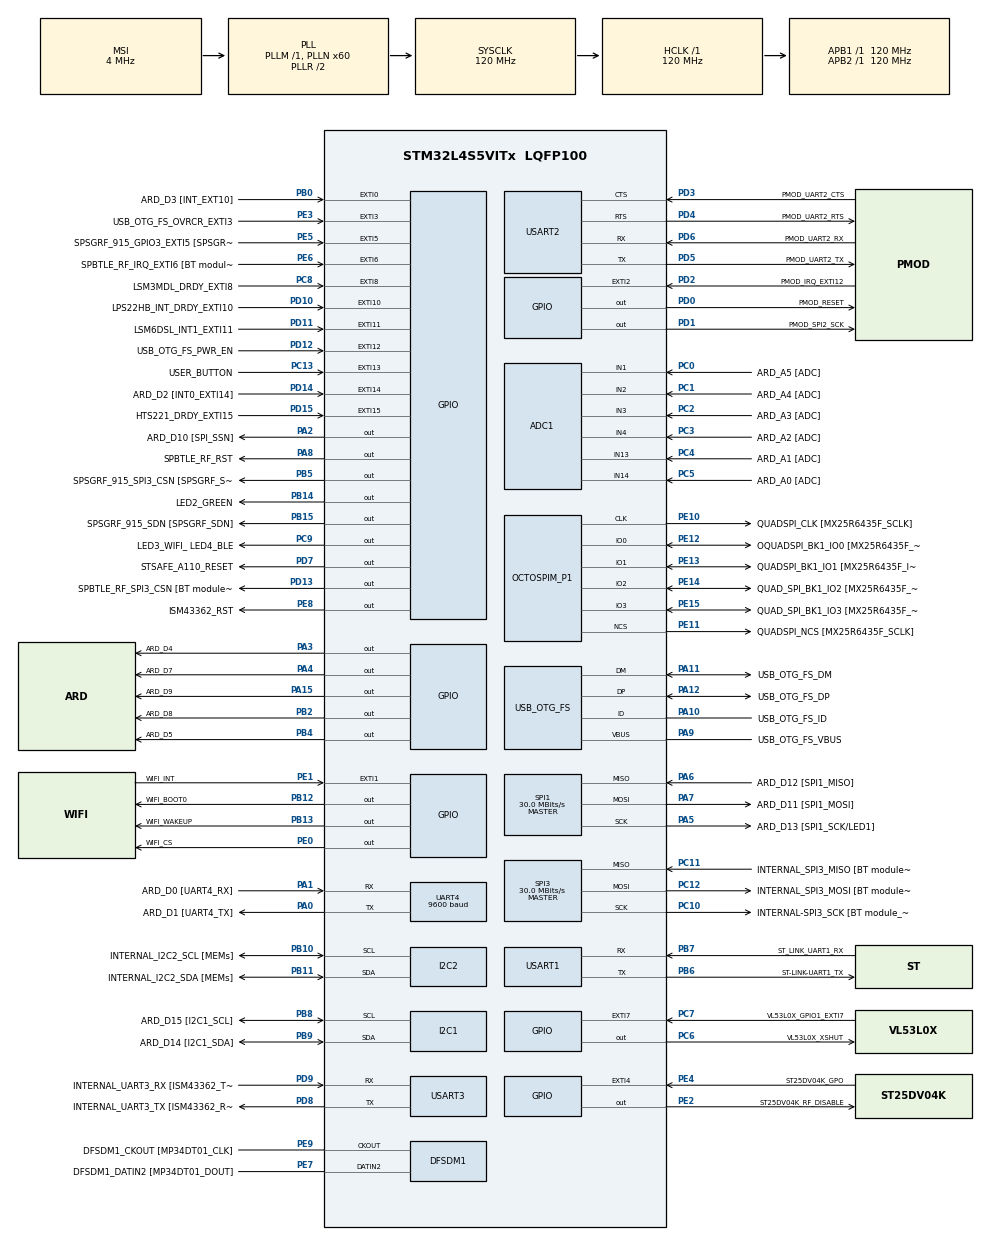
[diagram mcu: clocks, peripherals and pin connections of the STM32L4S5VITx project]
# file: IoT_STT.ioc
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ADC1.Channel-0\#ChannelRegularConversion=ADC_CHANNEL_1
ADC1.NbrOfConversionFlag=1
ADC1.OffsetNumber-0\#ChannelRegularConversion=ADC_OFFSET_NONE
ADC1.Rank-0\#ChannelRegularConversion=1
ADC1.SamplingTime-0\#ChannelRegularConversion=ADC_SAMPLETIME_2CYCLES_5
ADC1.master=1
I2C1.Timing=0x307075B1
I2C2.Timing=0x307075B1
Mcu.Family=STM32L4
Mcu.Name=STM32L4S5VITx
Mcu.Package=LQFP100
NVIC.EXTI15_10_IRQn=true\:0\:0\:false\:false\:true\:true\:true
NVIC.EXTI1_IRQn=true\:13\:0\:true\:false\:true\:true\:true
NVIC.EXTI9_5_IRQn=true\:0\:0\:false\:false\:true\:true\:true
NVIC.PriorityGroup=NVIC_PRIORITYGROUP_4
NVIC.SPI3_IRQn=true\:3\:0\:true\:false\:true\:true\:true
OCTOSPI1.MemoryType=HAL_OSPI_MEMTYPE_MACRONIX
PA0.GPIO_Label=ARD_D1 [UART4_TX]
PA0.GPIO_ModeDefaultPP=GPIO_MODE_AF_PP
PA0.GPIO_PuPd=GPIO_NOPULL
PA0.GPIO_Speed=GPIO_SPEED_FREQ_VERY_HIGH
PA0.Mode=Asynchronous
PA0.Signal=UART4_TX
PA1.GPIO_Label=ARD_D0 [UART4_RX]
PA1.GPIO_ModeDefaultPP=GPIO_MODE_AF_PP
PA1.GPIO_PuPd=GPIO_NOPULL
PA1.GPIO_Speed=GPIO_SPEED_FREQ_VERY_HIGH
PA1.Mode=Asynchronous
PA1.Signal=UART4_RX
PA10.GPIO_Label=USB_OTG_FS_ID
PA10.Mode=OTG/Dual_Role_Device
PA10.Signal=USB_OTG_FS_ID
PA11.GPIO_Label=USB_OTG_FS_DM
PA11.Mode=OTG/Dual_Role_Device
PA11.Signal=USB_OTG_FS_DM
PA12.GPIO_Label=USB_OTG_FS_DP
PA12.Mode=OTG/Dual_Role_Device
PA12.Signal=USB_OTG_FS_DP
PA13\ (JTMS/SWDIO).GPIO_Label=SYS_JTMS_SWDIO
PA13\ (JTMS/SWDIO).Mode=Serial_Wire
PA13\ (JTMS/SWDIO).Signal=SYS_JTMS-SWDIO
PA14\ (JTCK/SWCLK).GPIO_Label=SYS_JTCK_SWCLK
PA14\ (JTCK/SWCLK).Mode=Serial_Wire
PA14\ (JTCK/SWCLK).Signal=SYS_JTCK-SWCLK
PA15\ (JTDI).GPIO_Label=ARD_D9
PA15\ (JTDI).GPIO_ModeDefaultOutputPP=GPIO_MODE_OUTPUT_PP
PA15\ (JTDI).GPIO_PuPd=GPIO_NOPULL
PA15\ (JTDI).GPIO_Speed=GPIO_SPEED_FREQ_LOW
PA15\ (JTDI).PinState=GPIO_PIN_RESET
PA15\ (JTDI).Signal=GPIO_Output
PA2.GPIO_Label=ARD_D10 [SPI_SSN]
PA2.GPIO_ModeDefaultOutputPP=GPIO_MODE_OUTPUT_PP
PA2.GPIO_PuPd=GPIO_NOPULL
PA2.GPIO_Speed=GPIO_SPEED_FREQ_LOW
PA2.PinState=GPIO_PIN_RESET
PA2.Signal=GPIO_Output
PA3.GPIO_Label=ARD_D4
PA3.Signal=GPIO_Output
PA4.GPIO_Label=ARD_D7
PA4.Signal=GPIO_Output
PA5.GPIO_Label=ARD_D13 [SPI1_SCK/LED1]
PA5.GPIO_Mode=GPIO_MODE_AF_PP
PA5.GPIO_PuPd=GPIO_NOPULL
PA5.GPIO_Speed=GPIO_SPEED_FREQ_VERY_HIGH
PA5.Mode=Full_Duplex_Master
PA5.Signal=SPI1_SCK
PA6.GPIO_Label=ARD_D12 [SPI1_MISO]
PA6.GPIO_Mode=GPIO_MODE_AF_PP
PA6.GPIO_PuPd=GPIO_NOPULL
PA6.GPIO_Speed=GPIO_SPEED_FREQ_VERY_HIGH
PA6.Mode=Full_Duplex_Master
PA6.Signal=SPI1_MISO
PA7.GPIO_Label=ARD_D11 [SPI1_MOSI]
PA7.GPIO_Mode=GPIO_MODE_AF_PP
PA7.GPIO_PuPd=GPIO_NOPULL
PA7.GPIO_Speed=GPIO_SPEED_FREQ_VERY_HIGH
PA7.Mode=Full_Duplex_Master
PA7.Signal=SPI1_MOSI
PA8.GPIO_Label=SPBTLE_RF_RST
PA8.GPIO_ModeDefaultOutputPP=GPIO_MODE_OUTPUT_PP
PA8.GPIO_PuPd=GPIO_NOPULL
PA8.GPIO_Speed=GPIO_SPEED_FREQ_LOW
PA8.PinState=GPIO_PIN_RESET
PA8.Signal=GPIO_Output
PA9.GPIO_Label=USB_OTG_FS_VBUS
PA9.GPIO_Mode=GPIO_MODE_INPUT
PA9.GPIO_PuPd=GPIO_NOPULL
PA9.Mode=Activate_VBUS
PA9.Signal=USB_OTG_FS_VBUS
PB0.GPIO_Label=ARD_D3 [INT_EXT10]
PB0.GPIO_ModeDefaultEXTI=GPIO_MODE_IT_RISING
PB0.GPIO_PuPd=GPIO_NOPULL
PB0.Signal=GPXTI0
PB1.GPIO_Label=ARD_D6
PB1.GPIO_Speed=GPIO_SPEED_FREQ_LOW
PB1.Signal=S_TIM3_CH4
PB10.GPIO_Label=INTERNAL_I2C2_SCL [MEMs]
PB10.GPIO_Mode=GPIO_MODE_AF_OD
PB10.GPIO_PuPdOD=GPIO_PULLUP
PB10.GPIO_Speed=GPIO_SPEED_FREQ_VERY_HIGH
PB10.Mode=I2C
PB10.Signal=I2C2_SCL
PB11.GPIO_Label=INTERNAL_I2C2_SDA [MEMs]
PB11.GPIO_Mode=GPIO_MODE_AF_OD
PB11.GPIO_PuPdOD=GPIO_PULLUP
PB11.GPIO_Speed=GPIO_SPEED_FREQ_VERY_HIGH
PB11.Mode=I2C
PB11.Signal=I2C2_SDA
PB12.GPIO_Label=WIFI_BOOT0
PB12.GPIO_ModeDefaultOutputPP=GPIO_MODE_OUTPUT_PP
PB12.GPIO_PuPd=GPIO_NOPULL
PB12.GPIO_Speed=GPIO_SPEED_FREQ_LOW
PB12.PinState=GPIO_PIN_RESET
PB12.Signal=GPIO_Output
PB13.GPIO_Label=WIFI_WAKEUP
PB13.GPIO_ModeDefaultOutputPP=GPIO_MODE_OUTPUT_PP
PB13.GPIO_PuPd=GPIO_NOPULL
PB13.GPIO_Speed=GPIO_SPEED_FREQ_LOW
PB13.PinState=GPIO_PIN_RESET
PB13.Signal=GPIO_Output
PB14.GPIO_Label=LED2_GREEN
PB14.Signal=GPIO_Output
PB15.GPIO_Label=SPSGRF_915_SDN [SPSGRF_SDN]
PB15.Signal=GPIO_Output
PB2.GPIO_Label=ARD_D8
PB2.GPIO_ModeDefaultOutputPP=GPIO_MODE_OUTPUT_PP
PB2.GPIO_PuPd=GPIO_NOPULL
PB2.GPIO_Speed=GPIO_SPEED_FREQ_LOW
PB2.PinState=GPIO_PIN_RESET
PB2.Signal=GPIO_Output
PB3\ (JTDO/TRACESWO).GPIO_Label=SYS_JTD0_SWO
PB3\ (JTDO/TRACESWO).Signal=SYS_JTDO-SWO
PB4\ (NJTRST).GPIO_Label=ARD_D5
PB4\ (NJTRST).GPIO_ModeDefaultOutputPP=GPIO_MODE_OUTPUT_PP
PB4\ (NJTRST).GPIO_PuPd=GPIO_NOPULL
PB4\ (NJTRST).GPIO_Speed=GPIO_SPEED_FREQ_LOW
PB4\ (NJTRST).PinState=GPIO_PIN_RESET
PB4\ (NJTRST).Signal=GPIO_Output
PB5.GPIO_Label=SPSGRF_915_SPI3_CSN [SPSGRF_SPI_CS]
PB5.Signal=GPIO_Output
PB6.GPIO_FM6=__NULL
PB6.GPIO_Label=ST-LINK-UART1_TX
PB6.GPIO_ModeDefaultPP=GPIO_MODE_AF_PP
PB6.GPIO_PuPd=GPIO_NOPULL
PB6.GPIO_Speed=GPIO_SPEED_FREQ_VERY_HIGH
PB6.Mode=Asynchronous
PB6.Signal=USART1_TX
PB7.GPIO_FM7=__NULL
PB7.GPIO_Label=ST_LINK_UART1_RX
PB7.GPIO_ModeDefaultPP=GPIO_MODE_AF_PP
PB7.GPIO_PuPd=GPIO_NOPULL
PB7.GPIO_Speed=GPIO_SPEED_FREQ_VERY_HIGH
PB7.Mode=Asynchronous
PB7.Signal=USART1_RX
PB8.GPIO_FM8=__NULL
PB8.GPIO_Label=ARD_D15 [I2C1_SCL]
PB8.GPIO_Mode=GPIO_MODE_AF_OD
PB8.GPIO_PuPdOD=GPIO_PULLUP
PB8.GPIO_Speed=GPIO_SPEED_FREQ_VERY_HIGH
PB8.Mode=I2C
PB8.Signal=I2C1_SCL
PB9.GPIO_FM9=__NULL
PB9.GPIO_Label=ARD_D14 [I2C1_SDA]
PB9.GPIO_Mode=GPIO_MODE_AF_OD
PB9.GPIO_PuPdOD=GPIO_PULLUP
PB9.GPIO_Speed=GPIO_SPEED_FREQ_VERY_HIGH
PB9.Mode=I2C
PB9.Signal=I2C1_SDA
PC0.GPIO_Label=ARD_A5 [ADC]
PC0.GPIO_Mode=GPIO_MODE_ANALOG_ADC_CONTROL
PC0.GPIO_PuPd=GPIO_NOPULL
PC0.Signal=ADCx_IN1
PC1.GPIO_Label=ARD_A4 [ADC]
PC1.GPIO_Mode=GPIO_MODE_ANALOG_ADC_CONTROL
PC1.GPIO_PuPd=GPIO_NOPULL
PC1.Signal=ADCx_IN2
PC10.GPIO_Label=INTERNAL-SPI3_SCK [BT module_SPI_MOSI] [ISM43362_MOSI]
PC10.GPIO_Mode=GPIO_MODE_AF_PP
PC10.GPIO_PuPd=GPIO_NOPULL
PC10.GPIO_Speed=GPIO_SPEED_FREQ_VERY_HIGH
PC10.Mode=Full_Duplex_Master
PC10.Signal=SPI3_SCK
PC11.GPIO_Label=INTERNAL_SPI3_MISO [BT module_SPI_MOSI] [ISM43362_MOSI]
PC11.GPIO_Mode=GPIO_MODE_AF_PP
PC11.GPIO_PuPd=GPIO_NOPULL
PC11.GPIO_Speed=GPIO_SPEED_FREQ_VERY_HIGH
PC11.Mode=Full_Duplex_Master
PC11.Signal=SPI3_MISO
PC12.GPIO_Label=INTERNAL_SPI3_MOSI [BT module_SPI_MOSI] [ISM43362_MOSI]
PC12.GPIO_Mode=GPIO_MODE_AF_PP
PC12.GPIO_PuPd=GPIO_NOPULL
PC12.GPIO_Speed=GPIO_SPEED_FREQ_VERY_HIGH
PC12.Mode=Full_Duplex_Master
PC12.Signal=SPI3_MOSI
PC13.GPIO_Label=USER_BUTTON
PC13.Signal=GPXTI13
PC14-OSC32_IN\ (PC14).Mode=LSE-External-Oscillator
PC14-OSC32_IN\ (PC14).Signal=RCC_OSC32_IN
PC15-OSC32_OUT\ (PC15).Mode=LSE-External-Oscillator
PC15-OSC32_OUT\ (PC15).Signal=RCC_OSC32_OUT
PC2.GPIO_Label=ARD_A3 [ADC]
PC2.GPIO_Mode=GPIO_MODE_ANALOG_ADC_CONTROL
PC2.GPIO_PuPd=GPIO_NOPULL
PC2.Signal=ADCx_IN3
PC3.GPIO_Label=ARD_A2 [ADC]
PC3.GPIO_Mode=GPIO_MODE_ANALOG_ADC_CONTROL
PC3.GPIO_PuPd=GPIO_NOPULL
PC3.Signal=ADCx_IN4
PC4.GPIO_Label=ARD_A1 [ADC]
PC4.GPIO_Mode=GPIO_MODE_ANALOG_ADC_CONTROL
PC4.GPIO_PuPd=GPIO_NOPULL
PC4.Signal=ADCx_IN13
PC5.GPIO_Label=ARD_A0 [ADC]
PC5.GPIO_Mode=GPIO_MODE_ANALOG_ADC_CONTROL
PC5.GPIO_PuPd=GPIO_NOPULL
PC5.Signal=ADCx_IN14
PC6.GPIO_Label=VL53L0X_XSHUT
PC6.GPIO_ModeDefaultOutputPP=GPIO_MODE_OUTPUT_PP
PC6.GPIO_PuPd=GPIO_NOPULL
PC6.GPIO_Speed=GPIO_SPEED_FREQ_LOW
PC6.PinState=GPIO_PIN_RESET
PC6.Signal=GPIO_Output
PC7.GPIO_Label=VL53L0X_GPIO1_EXTI7
PC7.GPIO_ModeDefaultEXTI=GPIO_MODE_IT_RISING
PC7.GPIO_PuPd=GPIO_NOPULL
PC7.Signal=GPXTI7
PC8.GPIO_Label=LSM3MDL_DRDY_EXTI8
PC8.GPIO_ModeDefaultEXTI=GPIO_MODE_IT_RISING
PC8.GPIO_PuPd=GPIO_NOPULL
PC8.Signal=GPXTI8
PC9.GPIO_Label=LED3_WIFI_ LED4_BLE
PC9.GPIO_ModeDefaultOutputPP=GPIO_MODE_OUTPUT_PP
PC9.GPIO_PuPd=GPIO_NOPULL
PC9.GPIO_Speed=GPIO_SPEED_FREQ_LOW
PC9.PinState=GPIO_PIN_RESET
PC9.Signal=GPIO_Output
PD0.GPIO_Label=PMOD_RESET
PD0.GPIO_ModeDefaultOutputPP=GPIO_MODE_OUTPUT_PP
PD0.GPIO_PuPd=GPIO_NOPULL
PD0.GPIO_Speed=GPIO_SPEED_FREQ_LOW
PD0.PinState=GPIO_PIN_RESET
PD0.Signal=GPIO_Output
PD1.GPIO_Label=PMOD_SPI2_SCK
PD1.Signal=GPIO_Output
PD10.GPIO_Label=LPS22HB_INT_DRDY_EXTI10
PD10.GPIO_ModeDefaultEXTI=GPIO_MODE_IT_RISING
PD10.GPIO_PuPd=GPIO_NOPULL
PD10.Signal=GPXTI10
PD11.GPIO_Label=LSM6DSL_INT1_EXTI11
PD11.GPIO_ModeDefaultEXTI=GPIO_MODE_IT_RISING
PD11.GPIO_PuPd=GPIO_NOPULL
PD11.Signal=GPXTI11
PD12.GPIO_Label=USB_OTG_FS_PWR_EN
PD12.GPIO_ModeDefaultEXTI=GPIO_MODE_IT_RISING
PD12.GPIO_PuPd=GPIO_NOPULL
PD12.Signal=GPXTI12
PD13.GPIO_Label=SPBTLE_RF_SPI3_CSN [BT module_SPI_CS]
PD13.GPIO_ModeDefaultOutputPP=GPIO_MODE_OUTPUT_PP
PD13.GPIO_PuPd=GPIO_NOPULL
PD13.GPIO_Speed=GPIO_SPEED_FREQ_LOW
PD13.PinState=GPIO_PIN_RESET
PD13.Signal=GPIO_Output
PD14.GPIO_Label=ARD_D2 [INT0_EXTI14]
PD14.GPIO_ModeDefaultEXTI=GPIO_MODE_IT_RISING
PD14.GPIO_PuPd=GPIO_NOPULL
PD14.Signal=GPXTI14
PD15.GPIO_Label=HTS221_DRDY_EXTI15
PD15.GPIO_ModeDefaultEXTI=GPIO_MODE_IT_RISING
PD15.GPIO_PuPd=GPIO_NOPULL
PD15.Signal=GPXTI15
PD2.GPIO_Label=PMOD_IRQ_EXTI12
PD2.GPIO_ModeDefaultEXTI=GPIO_MODE_IT_RISING
PD2.GPIO_PuPd=GPIO_NOPULL
PD2.Signal=GPXTI2
PD3.GPIO_Label=PMOD_UART2_CTS
PD3.GPIO_Mode=GPIO_MODE_AF_PP
PD3.GPIO_PuPd=GPIO_NOPULL
PD3.GPIO_Speed=GPIO_SPEED_FREQ_VERY_HIGH
PD3.Mode=CTS_RTS
PD3.Signal=USART2_CTS
PD4.GPIO_Label=PMOD_UART2_RTS
PD4.GPIO_Mode=GPIO_MODE_AF_PP
PD4.GPIO_PuPd=GPIO_NOPULL
PD4.GPIO_Speed=GPIO_SPEED_FREQ_VERY_HIGH
PD4.Mode=CTS_RTS
PD4.Signal=USART2_RTS
PD5.GPIO_Label=PMOD_UART2_TX
PD5.GPIO_ModeDefaultPP=GPIO_MODE_AF_PP
PD5.GPIO_PuPd=GPIO_NOPULL
PD5.GPIO_Speed=GPIO_SPEED_FREQ_VERY_HIGH
PD5.Mode=Asynchronous
PD5.Signal=USART2_TX
PD6.GPIO_Label=PMOD_UART2_RX
PD6.GPIO_ModeDefaultPP=GPIO_MODE_AF_PP
PD6.GPIO_PuPd=GPIO_NOPULL
PD6.GPIO_Speed=GPIO_SPEED_FREQ_VERY_HIGH
PD6.Mode=Asynchronous
PD6.Signal=USART2_RX
PD7.GPIO_Label=STSAFE_A110_RESET
PD7.GPIO_ModeDefaultOutputPP=GPIO_MODE_OUTPUT_PP
PD7.GPIO_PuPd=GPIO_NOPULL
PD7.GPIO_Speed=GPIO_SPEED_FREQ_LOW
PD7.PinState=GPIO_PIN_RESET
PD7.Signal=GPIO_Output
PD8.GPIO_Label=INTERNAL_UART3_TX [ISM43362_RX]
PD8.GPIO_ModeDefaultPP=GPIO_MODE_AF_PP
PD8.GPIO_PuPd=GPIO_NOPULL
PD8.GPIO_Speed=GPIO_SPEED_FREQ_VERY_HIGH
PD8.Mode=Asynchronous
PD8.Signal=USART3_TX
PD9.GPIO_Label=INTERNAL_UART3_RX [ISM43362_TX]
PD9.GPIO_ModeDefaultPP=GPIO_MODE_AF_PP
PD9.GPIO_PuPd=GPIO_NOPULL
PD9.GPIO_Speed=GPIO_SPEED_FREQ_VERY_HIGH
PD9.Mode=Asynchronous
PD9.Signal=USART3_RX
PE0.GPIO_Label=WIFI_CS
PE0.Signal=GPIO_Output
PE1.GPIO_Label=WIFI_INT
PE1.Signal=GPXTI1
PE10.GPIO_Label=QUADSPI_CLK [MX25R6435F_SCLK]
PE10.GPIO_Mode=GPIO_MODE_AF_PP
PE10.GPIO_PuPd=GPIO_NOPULL
PE10.GPIO_Speed_High_Default=GPIO_SPEED_FREQ_VERY_HIGH
PE10.Mode=O1_P1_CLK
PE10.Signal=OCTOSPIM_P1_CLK
PE11.GPIO_Label=QUADSPI_NCS [MX25R6435F_SCLK]
PE11.GPIO_Mode=GPIO_MODE_AF_PP
PE11.GPIO_PuPd=GPIO_NOPULL
PE11.GPIO_Speed_High_Default=GPIO_SPEED_FREQ_VERY_HIGH
PE11.Mode=OCTOSPI1_Port1_NCS
PE11.Signal=OCTOSPIM_P1_NCS
PE12.GPIO_Label=OQUADSPI_BK1_IO0 [MX25R6435F_IO0]
PE12.GPIO_Mode=GPIO_MODE_AF_PP
PE12.GPIO_PuPd=GPIO_NOPULL
PE12.GPIO_Speed_High_Default=GPIO_SPEED_FREQ_VERY_HIGH
PE12.Mode=OCTOSPI1_IOL_Port1L
PE12.Signal=OCTOSPIM_P1_IO0
PE13.GPIO_Label=QUADSPI_BK1_IO1 [MX25R6435F_IO1]
PE13.GPIO_Mode=GPIO_MODE_AF_PP
PE13.GPIO_PuPd=GPIO_NOPULL
PE13.GPIO_Speed_High_Default=GPIO_SPEED_FREQ_VERY_HIGH
PE13.Mode=OCTOSPI1_IOL_Port1L
PE13.Signal=OCTOSPIM_P1_IO1
PE14.GPIO_Label=QUAD_SPI_BK1_IO2 [MX25R6435F_IO2]
PE14.GPIO_Mode=GPIO_MODE_AF_PP
PE14.GPIO_PuPd=GPIO_NOPULL
PE14.GPIO_Speed_High_Default=GPIO_SPEED_FREQ_VERY_HIGH
PE14.Mode=OCTOSPI1_IOL_Port1L
PE14.Signal=OCTOSPIM_P1_IO2
PE15.GPIO_Label=QUAD_SPI_BK1_IO3 [MX25R6435F_IO3]
PE15.GPIO_Mode=GPIO_MODE_AF_PP
PE15.GPIO_PuPd=GPIO_NOPULL
PE15.GPIO_Speed_High_Default=GPIO_SPEED_FREQ_VERY_HIGH
PE15.Mode=OCTOSPI1_IOL_Port1L
PE15.Signal=OCTOSPIM_P1_IO3
PE2.GPIO_Label=ST25DV04K_RF_DISABLE
PE2.GPIO_ModeDefaultOutputPP=GPIO_MODE_OUTPUT_PP
PE2.GPIO_PuPd=GPIO_NOPULL
PE2.GPIO_Speed=GPIO_SPEED_FREQ_LOW
PE2.PinState=GPIO_PIN_RESET
PE2.Signal=GPIO_Output
PE3.GPIO_Label=USB_OTG_FS_OVRCR_EXTI3
PE3.GPIO_ModeDefaultEXTI=GPIO_MODE_IT_RISING
PE3.GPIO_PuPd=GPIO_NOPULL
PE3.Signal=GPXTI3
PE4.GPIO_Label=ST25DV04K_GPO
PE4.GPIO_ModeDefaultEXTI=GPIO_MODE_IT_RISING
PE4.GPIO_PuPd=GPIO_NOPULL
PE4.Signal=GPXTI4
PE5.GPIO_Label=SPSGRF_915_GPIO3_EXTI5 [SPSGRF_GPIO_3]
PE5.Signal=GPXTI5
PE6.GPIO_Label=SPBTLE_RF_IRQ_EXTI6 [BT module_SPI_IRQ]
PE6.GPIO_ModeDefaultEXTI=GPIO_MODE_IT_RISING
PE6.GPIO_PuPd=GPIO_NOPULL
PE6.Signal=GPXTI6
PE7.GPIO_Label=DFSDM1_DATIN2 [MP34DT01_DOUT]
PE7.GPIO_Mode=GPIO_MODE_AF_PP
PE7.GPIO_PuPd=GPIO_NOPULL
PE7.GPIO_Speed=GPIO_SPEED_FREQ_LOW
PE7.Signal=S_DATAIN2DFSDM1
PE8.GPIO_Label=ISM43362_RST
PE8.GPIO_ModeDefaultOutputPP=GPIO_MODE_OUTPUT_PP
PE8.GPIO_PuPd=GPIO_NOPULL
PE8.GPIO_Speed=GPIO_SPEED_FREQ_LOW
PE8.PinState=GPIO_PIN_RESET
PE8.Signal=GPIO_Output
PE9.GPIO_Label=DFSDM1_CKOUT [MP34DT01_CLK]
PE9.GPIO_Mode=GPIO_MODE_AF_PP
PE9.GPIO_PuPd=GPIO_NOPULL
PE9.GPIO_Speed=GPIO_SPEED_FREQ_LOW
PE9.Signal=S_CKOUTDFSDM1
PH0-OSC_IN\ (PH0).Mode=HSE-External-Oscillator
PH0-OSC_IN\ (PH0).Signal=RCC_OSC_IN
PH1-OSC_OUT\ (PH1).Mode=HSE-External-Oscillator
PH1-OSC_OUT\ (PH1).Signal=RCC_OSC_OUT
ProjectManager.HeapSize=0x200
ProjectManager.StackSize=0x400
ProjectManager.TargetToolchain=STM32CubeIDE
RCC.ADCFreq_Value=48000000
RCC.AHBFreq_Value=120000000
RCC.APB1Freq_Value=120000000
RCC.APB1TimFreq_Value=120000000
RCC.APB2Freq_Value=120000000
RCC.APB2TimFreq_Value=120000000
RCC.CortexFreq_Value=120000000
RCC.HCLKFreq_Value=120000000
RCC.HSE_VALUE=8000000
RCC.HSI48_VALUE=48000000
RCC.HSI_VALUE=16000000
RCC.MSI_VALUE=4000000
RCC.PLLN=60
RCC.PLLSAI1N=24
RCC.SYSCLKFreq_VALUE=120000000
RCC.SYSCLKSource=RCC_SYSCLKSOURCE_PLLCLK
RCC.USBFreq_Value=48000000
RCC.VCOOutputFreq_Value=240000000
SH.ADCx_IN1.0=ADC1_IN1,IN1-Single-Ended
SH.ADCx_IN13.0=ADC1_IN13,IN13-Single-Ended
SH.ADCx_IN14.0=ADC1_IN14,IN14-Single-Ended
SH.ADCx_IN2.0=ADC1_IN2,IN2-Single-Ended
SH.ADCx_IN3.0=ADC1_IN3,IN3-Single-Ended
SH.ADCx_IN4.0=ADC1_IN4,IN4-Single-Ended
SH.S_CKOUTDFSDM1.0=DFSDM1_CKOUT,PDM_SPI_input_from_ch2_and_internal_clock
SH.S_DATAIN2DFSDM1.0=DFSDM1_DATIN2,PDM_SPI_input_from_ch2_and_internal_clock
SH.S_TIM3_CH4.0=TIM3_CH4
SPI1.BaudRatePrescaler=SPI_BAUDRATEPRESCALER_4
SPI1.CalculateBaudRate=30.0 MBits/s
SPI1.DataSize=SPI_DATASIZE_4BIT
SPI1.Direction=SPI_DIRECTION_2LINES
SPI1.Mode=SPI_MODE_MASTER
SPI1.VirtualType=VM_MASTER
SPI3.BaudRatePrescaler=SPI_BAUDRATEPRESCALER_4
SPI3.CalculateBaudRate=30.0 MBits/s
SPI3.Direction=SPI_DIRECTION_2LINES
SPI3.Mode=SPI_MODE_MASTER
SPI3.VirtualType=VM_MASTER
UART4.BaudRate=9600
USART1.VirtualMode-Asynchronous=VM_ASYNC
USART2.VirtualMode-Asynchronous=VM_ASYNC
USART3.VirtualMode-Asynchronous=VM_ASYNC
VP_OCTOSPI1_VS_quad.Mode=quad_mode
board=B-L4S5I-IOT01A

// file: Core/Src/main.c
/* USER CODE BEGIN Header */
/**
  ******************************************************************************
  * @file           : main.c
  * @brief          : Main program body
  ******************************************************************************
  * @attention
  *
  * <h2><center>&copy; Copyright (c) 2020 STMicroelectronics.
  * All rights reserved.</center></h2>
  *
  * This software component is licensed by ST under BSD 3-Clause license,
  * the "License"; You may not use this file except in compliance with the
  * License. You may obtain a copy of the License at:
  *                        opensource.org/licenses/BSD-3-Clause
  *
  ******************************************************************************
  */
/* USER CODE END Header */
#include "main.h"
#include "adc.h"
#include "dfsdm.h"
#include "i2c.h"
#include "octospi.h"
#include "spi.h"
#include "usart.h"
#include "usb_otg.h"
#include "gpio.h"

/* USER CODE BEGIN Includes */
#include <stdio.h>
#include "../../Drivers/ES_WIFI/es_wifi_io.h"
#include "../../Drivers/ES_WIFI/wifi.h"
/* USER CODE END Includes */

/* USER CODE BEGIN PD */
#define SOCKET_NUM (0)
#define TIMEOUT (20)
#define BUF_SZ (1024)
/* USER CODE END PD */

void SystemClock_Config(void);

/* USER CODE BEGIN 0 */
int __io_putchar(int ch)
{
	if (ch == '\n')
	{
		uint8_t send_data[2] = {'\r','\n'};
		HAL_UART_Transmit(&huart1, send_data, 2, 1);
	}
	else
	{
		while (HAL_OK != HAL_UART_Transmit(&huart1, (uint8_t *) & ch, 1, 30000))
		{

		}
	}
	return ch;
}

//int __io_getchar(void)
//{
//  uint8_t ch = 0;
//  while (HAL_OK != HAL_UART_Receive(&huart1, (uint8_t *)&ch, 1, 30000))
//  {
//  }
//  return ch;
//}

int _read(int32_t file, uint8_t *result, int32_t len)
{
    HAL_StatusTypeDef status;
    int retcode = 0;

    if (len != 0) {
        status = HAL_UART_Receive( &huart1, (uint8_t *) result, len, HAL_MAX_DELAY);
        if (status == HAL_OK) {
            retcode = len;
        } else {
            retcode = -1;
        }
    }
    return(retcode);
}

void Nextion_Send_String(char *Id, char *String)
{
	uint8_t Cmd_End[3] = { 0xFF, 0xFF, 0xFF};
	char buf[50];
	int len = sprintf(buf, "%s.txt=\"%s\"", Id, String);
	printf("Stringr=%s\n", buf);
	HAL_UART_Transmit(&huart4, (uint8_t *)buf, len, 1000);
	HAL_UART_Transmit(&huart4, Cmd_End, sizeof(Cmd_End), 1000);
}

void Nextion_Send_Number(char *Id, int no)
{
	uint8_t Cmd_End[3] = { 0xFF, 0xFF, 0xFF};
	char buf[50];
	int len = sprintf(buf, "%s.val=%d", Id, no);
	printf("Number=%s\n", buf);
	HAL_UART_Transmit(&huart4, (uint8_t *)buf, len, 1000);
	HAL_UART_Transmit(&huart4, Cmd_End, sizeof(Cmd_End), 1000);
}

/* USER CODE END 0 */

int main(void)
{
  /* USER CODE BEGIN 1 */
	char *SSID = "jmkim";
	char *PASSWD = "qaz12345";
    char req_data[BUF_SZ];
#ifdef THINGSPARK
    uint16_t sent_data_len = 0;
	float field1, field2;
#endif
	int count = 0;

  /* USER CODE END 1 */

  /* MCU Configuration--------------------------------------------------------*/

  /* Reset of all peripherals, Initializes the Flash interface and the Systick. */
  HAL_Init();

  /* Configure the system clock */
  SystemClock_Config();

  /* Initialize all configured peripherals */
  MX_GPIO_Init();
  MX_ADC1_Init();
  MX_DFSDM1_Init();
  MX_I2C1_Init();
  MX_I2C2_Init();
  MX_OCTOSPI1_Init();
  MX_SPI1_Init();
  MX_SPI3_Init();
  MX_UART4_Init();
  MX_USART1_UART_Init();
  MX_USART2_UART_Init();
  MX_USART3_UART_Init();
  MX_USB_OTG_FS_USB_Init();
  /* USER CODE BEGIN 2 */
  printf("WIFI Init ...\n");
      WIFI_Status_t ret = WIFI_Init();
      if (ret != WIFI_STATUS_OK) {
        printf("Failed to initialize Wi-Fi [%d]\n", ret);
      }
      uint8_t  MAC_Addr[6];
      if(WIFI_GetMAC_Address(MAC_Addr) == WIFI_STATUS_OK)
      {
      	printf("WIFI MAC Address : %X:%X:%X:%X:%X:%X\n",
      	MAC_Addr[0], MAC_Addr[1], MAC_Addr[2],
      	MAC_Addr[3], MAC_Addr[4], MAC_Addr[5]);
      }
      else
      {
      	printf("> ERROR : CANNOT get MAC address\r\n");
      }

      printf("WIFI Connect to %s ...\n", SSID);
      ret = WIFI_Connect(SSID, PASSWD, WIFI_ECN_WPA2_PSK);
      if (ret != WIFI_STATUS_OK)
      {
        printf("Failed to connect AP [%d]\n", ret);
      }

      uint8_t IP_Addr[4];
      if(WIFI_GetIP_Address(IP_Addr) == WIFI_STATUS_OK)
      {
        printf("WIFI IP Address : %d.%d.%d.%d\n",
        IP_Addr[0], IP_Addr[1],	IP_Addr[2], IP_Addr[3]);
        sprintf(req_data, "WIFI IP Address : %d.%d.%d.%d",
                IP_Addr[0], IP_Addr[1],	IP_Addr[2], IP_Addr[3]);
        Nextion_Send_String("t1", req_data);
        printf("send WIFI IP Address : %s\n", req_data);
        HAL_Delay(1000);
      }
  /* USER CODE END 2 */

  /* Infinite loop */
  /* USER CODE BEGIN WHILE */
	printf("Connect to thinspark\n");
	bzero(req_data, BUF_SZ);

  while (1)
  {
	  char sbuf[100];
//	  // USER_Button delete
//	  HAL_GPIO_TogglePin(LED2_GREEN_GPIO_Port, LED2_GREEN_Pin);
//	  HAL_Delay(1000);

// THINGSPARK
//	field1 = (float) HAL_GetTick();
	printf("count = %d\n", ++count);
	Nextion_Send_Number("n0", count);
	HAL_Delay(1000);
	sprintf(sbuf, "Try %6ld", HAL_GetTick()); //
	printf("%s\n", sbuf);
	Nextion_Send_String("t1", sbuf);
	HAL_Delay(1000);

#ifdef THINSPARK
	  uint8_t ipAddr[4];
	  ret = WIFI_GetHostAddress("api.thingspark.co.kr", ipAddr);
	  if (ret != WIFI_STATUS_OK)
	  {
		  printf("Failed to get host address [%d]\n", ret);
		  return (-1);
	  } else
	  {
		  printf("WIFI thingspark-connect\n");
	  }
	  ret = WIFI_OpenClientConnection(SOCKET_NUM, WIFI_TCP_PROTOCOL, "cloud-connect", ipAddr, 8480, 0);
	  HAL_Delay(1000);
	  if (ret != WIFI_STATUS_OK)
	  {
		  printf("Failed to connect to server [%d]\r\n", ret);
	  }

	  field1 = (float) HAL_GetTick();
	  field2 = 99.99;
	  sprintf(req_data,"GET /update?apiKey=1Goxe9xWIuw2uk84&field1=%f&field2=%f\r\n", field1, field2);

	  WIFI_SendData(SOCKET_NUM, (uint8_t *)req_data, sizeof(req_data), &sent_data_len, TIMEOUT);
	  HAL_Delay(1000);
	  WIFI_CloseClientConnection(SOCKET_NUM);
#endif

    /* USER CODE END WHILE */

  }
}

void SystemClock_Config(void)
{
  RCC_OscInitTypeDef RCC_OscInitStruct = {0};
  RCC_ClkInitTypeDef RCC_ClkInitStruct = {0};
  RCC_PeriphCLKInitTypeDef PeriphClkInit = {0};

  /** Configure the main internal regulator output voltage
  */
  if (HAL_PWREx_ControlVoltageScaling(PWR_REGULATOR_VOLTAGE_SCALE1_BOOST) != HAL_OK)
  {
    Error_Handler();
  }
  /** Configure LSE Drive Capability
  */
  HAL_PWR_EnableBkUpAccess();
  __HAL_RCC_LSEDRIVE_CONFIG(RCC_LSEDRIVE_LOW);
  /** Initializes the RCC Oscillators according to the specified parameters
  * in the RCC_OscInitTypeDef structure.
  */
  RCC_OscInitStruct.OscillatorType = RCC_OSCILLATORTYPE_LSE|RCC_OSCILLATORTYPE_MSI;
  RCC_OscInitStruct.LSEState = RCC_LSE_ON;
  RCC_OscInitStruct.MSIState = RCC_MSI_ON;
  RCC_OscInitStruct.MSICalibrationValue = 0;
  RCC_OscInitStruct.MSIClockRange = RCC_MSIRANGE_6;
  RCC_OscInitStruct.PLL.PLLState = RCC_PLL_ON;
  RCC_OscInitStruct.PLL.PLLSource = RCC_PLLSOURCE_MSI;
  RCC_OscInitStruct.PLL.PLLM = 1;
  RCC_OscInitStruct.PLL.PLLN = 60;
  RCC_OscInitStruct.PLL.PLLP = RCC_PLLP_DIV2;
  RCC_OscInitStruct.PLL.PLLQ = RCC_PLLQ_DIV2;
  RCC_OscInitStruct.PLL.PLLR = RCC_PLLR_DIV2;
  if (HAL_RCC_OscConfig(&RCC_OscInitStruct) != HAL_OK)
  {
    Error_Handler();
  }
  /** Initializes the CPU, AHB and APB buses clocks
  */
  RCC_ClkInitStruct.ClockType = RCC_CLOCKTYPE_HCLK|RCC_CLOCKTYPE_SYSCLK
                              |RCC_CLOCKTYPE_PCLK1|RCC_CLOCKTYPE_PCLK2;
  RCC_ClkInitStruct.SYSCLKSource = RCC_SYSCLKSOURCE_PLLCLK;
  RCC_ClkInitStruct.AHBCLKDivider = RCC_SYSCLK_DIV1;
  RCC_ClkInitStruct.APB1CLKDivider = RCC_HCLK_DIV1;
  RCC_ClkInitStruct.APB2CLKDivider = RCC_HCLK_DIV1;

  if (HAL_RCC_ClockConfig(&RCC_ClkInitStruct, FLASH_LATENCY_5) != HAL_OK)
  {
    Error_Handler();
  }
  PeriphClkInit.PeriphClockSelection = RCC_PERIPHCLK_USART1|RCC_PERIPHCLK_USART2
                              |RCC_PERIPHCLK_USART3|RCC_PERIPHCLK_UART4
                              |RCC_PERIPHCLK_I2C1|RCC_PERIPHCLK_I2C2
                              |RCC_PERIPHCLK_DFSDM1|RCC_PERIPHCLK_USB
                              |RCC_PERIPHCLK_ADC|RCC_PERIPHCLK_OSPI;
  PeriphClkInit.Usart1ClockSelection = RCC_USART1CLKSOURCE_PCLK2;
  PeriphClkInit.Usart2ClockSelection = RCC_USART2CLKSOURCE_PCLK1;
  PeriphClkInit.Usart3ClockSelection = RCC_USART3CLKSOURCE_PCLK1;
  PeriphClkInit.Uart4ClockSelection = RCC_UART4CLKSOURCE_PCLK1;
  PeriphClkInit.I2c1ClockSelection = RCC_I2C1CLKSOURCE_PCLK1;
  PeriphClkInit.I2c2ClockSelection = RCC_I2C2CLKSOURCE_PCLK1;
  PeriphClkInit.AdcClockSelection = RCC_ADCCLKSOURCE_PLLSAI1;
  PeriphClkInit.Dfsdm1ClockSelection = RCC_DFSDM1CLKSOURCE_PCLK;
  PeriphClkInit.OspiClockSelection = RCC_OSPICLKSOURCE_SYSCLK;
  PeriphClkInit.UsbClockSelection = RCC_USBCLKSOURCE_PLLSAI1;
  PeriphClkInit.PLLSAI1.PLLSAI1Source = RCC_PLLSOURCE_MSI;
  PeriphClkInit.PLLSAI1.PLLSAI1M = 1;
  PeriphClkInit.PLLSAI1.PLLSAI1N = 24;
  PeriphClkInit.PLLSAI1.PLLSAI1P = RCC_PLLP_DIV2;
  PeriphClkInit.PLLSAI1.PLLSAI1Q = RCC_PLLQ_DIV2;
  PeriphClkInit.PLLSAI1.PLLSAI1R = RCC_PLLR_DIV2;
  PeriphClkInit.PLLSAI1.PLLSAI1ClockOut = RCC_PLLSAI1_48M2CLK|RCC_PLLSAI1_ADC1CLK;
  if (HAL_RCCEx_PeriphCLKConfig(&PeriphClkInit) != HAL_OK)
  {
    Error_Handler();
  }
  /** Enable MSI Auto calibration
  */
  HAL_RCCEx_EnableMSIPLLMode();
}

/* USER CODE BEGIN 4 */
void HAL_GPIO_EXTI_Callback(uint16_t GPIO_Pin)
{
	if (GPIO_Pin == USER_BUTTON_Pin)
	{
		HAL_GPIO_TogglePin(LED2_GREEN_GPIO_Port, LED2_GREEN_Pin);
	}
}
/* USER CODE END 4 */

void Error_Handler(void)
{
  __disable_irq();
  while (1)
  {
  }
}

/************************ (C) COPYRIGHT STMicroelectronics *****END OF FILE****/
